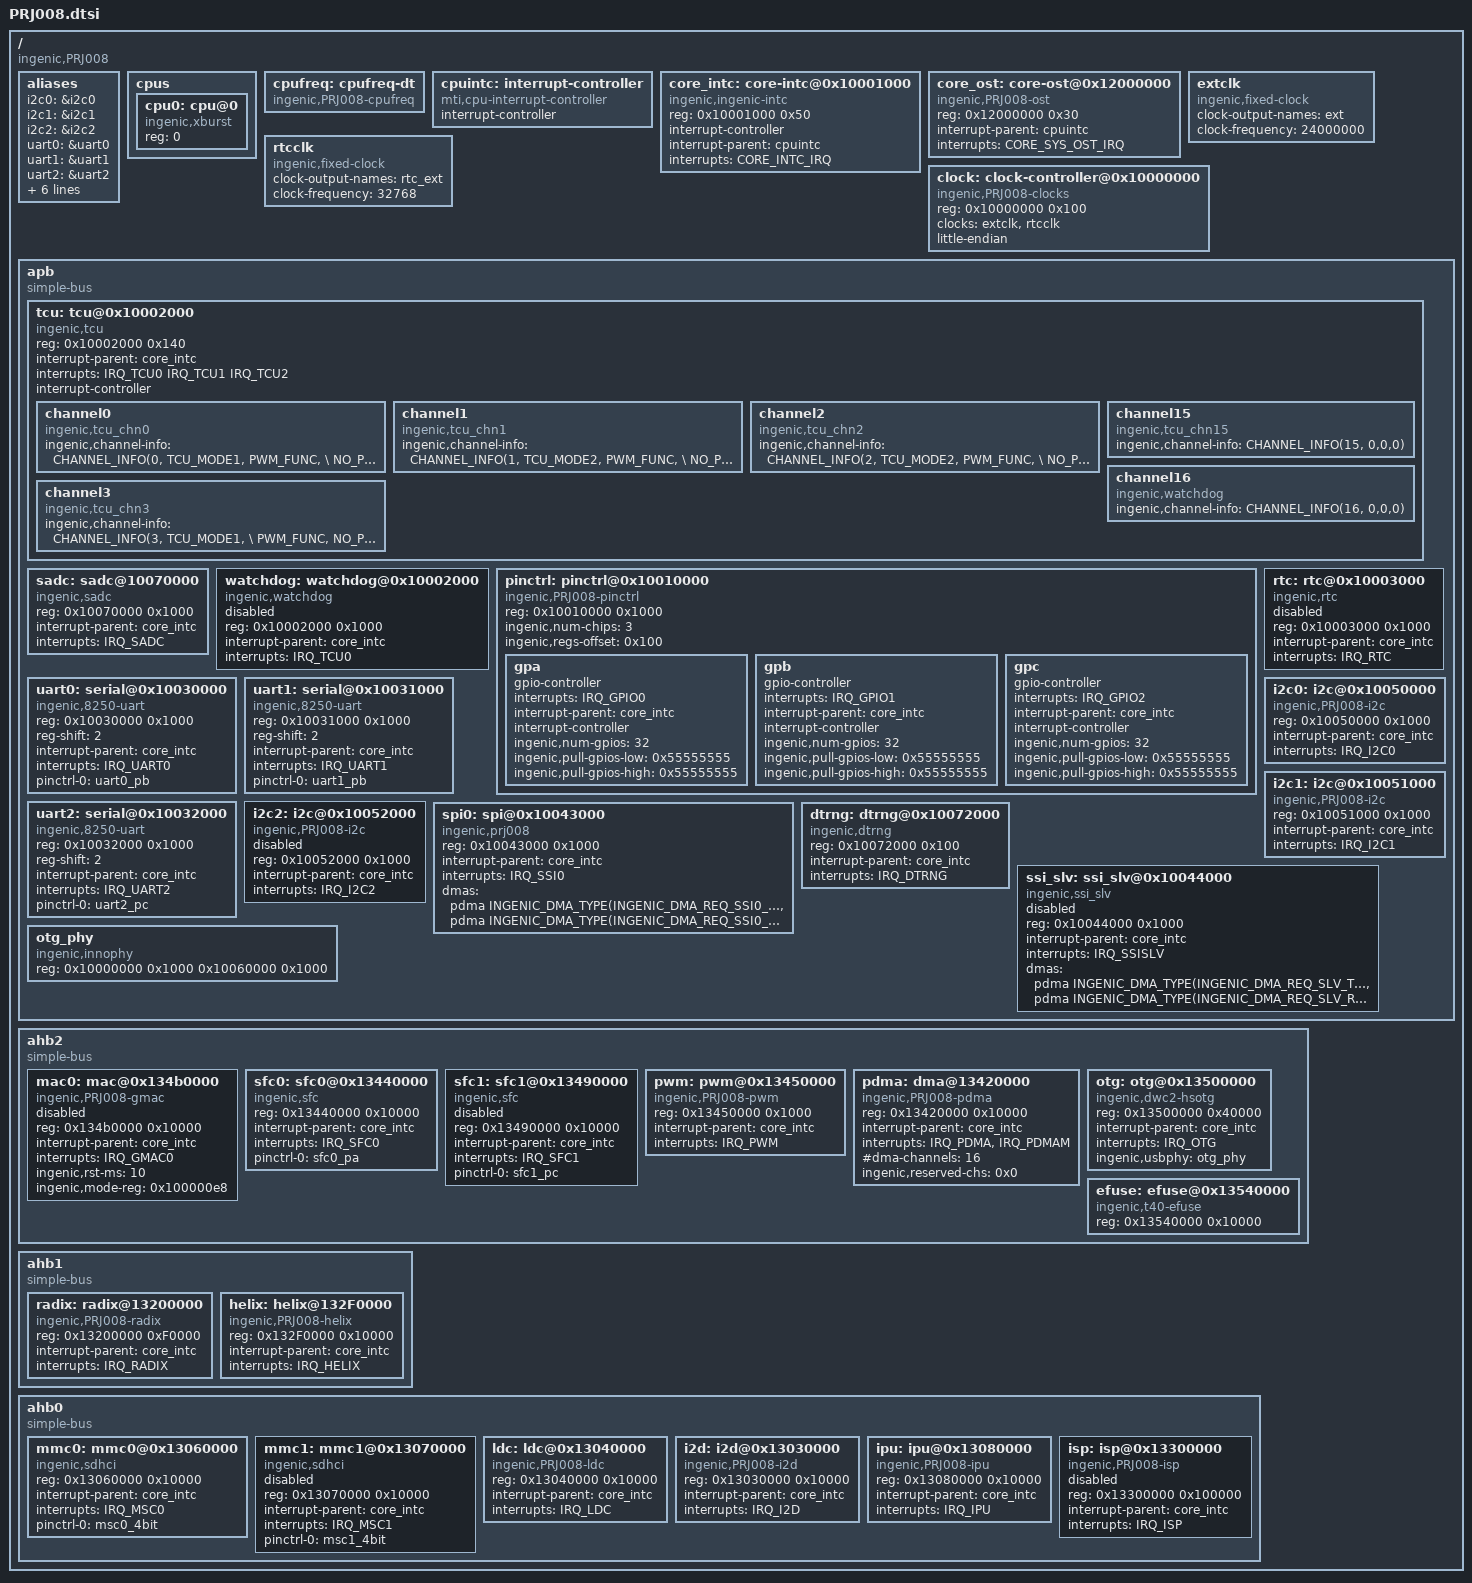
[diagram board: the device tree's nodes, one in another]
#include <dt-bindings/interrupt-controller/PRJ008-irq.h>
#include <dt-bindings/clock/ingenic-tcu.h>
#include <dt-bindings/sound/ingenic-baic.h>
#include <dt-bindings/net/ingenic_gmac.h>
#include <dt-bindings/dma/ingenic-pdma.h>

/ {
	#address-cells = <1>;
	#size-cells = <1>;
	compatible = "ingenic,PRJ008";

	aliases: aliases {
		i2c0 = &i2c0;
		i2c1 = &i2c1;
		i2c2 = &i2c2;
		uart0 = &uart0;
		uart1 = &uart1;
		uart2 = &uart2;
		mmc0 = &mmc0;
		mmc1 = &mmc1;
		mac0 = &mac0;
		spi0 = &spi0;
		sfc0 = &sfc0;
		sfc1 = &sfc1;
	};

	cpus: cpus {
		#address-cells = <1>;
		#size-cells = <0>;

		cpu0: cpu@0 {
			compatible = "ingenic,xburst";
			reg = <0>;
//			clock-frequency = <900000000>;
		};
	};

	cpufreq: cpufreq-dt {
		 compatible = "ingenic,PRJ008-cpufreq";
		 status = "okay";
	};

	cpuintc: interrupt-controller {
		#address-cells = <0>;
		#interrupt-cells = <1>;
		interrupt-controller;
//		compatible = "ingenic,cpu-interrupt-controller";
		compatible = "mti,cpu-interrupt-controller";

	};

	core_intc: core-intc@0x10001000 {
		compatible = "ingenic,ingenic-intc";
		reg = <0x10001000 0x50>;
		interrupt-controller;
		#interrupt-cells = <1>;
		/*cpu-intc-map = <0 0x000>,
			           <1 0x100>,
			           <2 0x200>,
			           <3 0x300>;
*/
		interrupt-parent = <&cpuintc>;
		interrupts = <CORE_INTC_IRQ>;
		interrupt-names ="intc";
	};

	core_ost: core-ost@0x12000000 {
		compatible = "ingenic,PRJ008-ost";
		reg = <0x12000000 0x30>;
		interrupt-parent = <&cpuintc>;
		interrupt-names = "sys_ost";
		interrupts = <CORE_SYS_OST_IRQ>;
	};

	extclk: extclk {
		compatible = "ingenic,fixed-clock";
		clock-output-names ="ext";
		#clock-cells = <0>;
		clock-frequency  = <24000000>;
	};

	rtcclk: rtcclk {
		compatible = "ingenic,fixed-clock";
		clock-output-names ="rtc_ext";
		#clock-cells = <0>;
		clock-frequency = <32768>;
    };

	clock: clock-controller@0x10000000 {
		compatible = "ingenic,PRJ008-clocks";
		reg = <0x10000000 0x100>;
		clocks = <&extclk>, <&rtcclk>;
		clock-names = "ext", "rtc_ext";
		#clock-cells = <1>;
		little-endian;
	};

	apb {
		compatible = "simple-bus";
		#address-cells = <1>;
		#size-cells = <1>;
		ranges = <>;
		tcu: tcu@0x10002000 {
				compatible = "ingenic,tcu";
				reg = <0x10002000 0x140>;
				interrupt-parent = <&core_intc>;
				interrupt-names = "tcu_int0", "tcu_int1", "tcu_int2";
				interrupts = <IRQ_TCU0 IRQ_TCU1 IRQ_TCU2>;
				interrupt-controller;
				status = "ok";

				channel0: channel0 {
					compatible = "ingenic,tcu_chn0";
					ingenic,channel-info = <CHANNEL_INFO(0, TCU_MODE1, PWM_FUNC, \
					NO_PWM_IN)>;
				};
				channel1: channel1 {
					compatible = "ingenic,tcu_chn1";
					ingenic,channel-info = <CHANNEL_INFO(1, TCU_MODE2, PWM_FUNC, \
					NO_PWM_IN)>;
				};
				channel2: channel2 {
					compatible = "ingenic,tcu_chn2";
					ingenic,channel-info = <CHANNEL_INFO(2, TCU_MODE2, PWM_FUNC, \
					NO_PWM_IN)>;
				};
				channel3: channel3 {
					compatible = "ingenic,tcu_chn3";
					ingenic,channel-info = <CHANNEL_INFO(3, TCU_MODE1, \
					PWM_FUNC, NO_PWM_IN)>;
				};
				channel15: channel15 {
					compatible = "ingenic,tcu_chn15";
					ingenic,channel-info = <CHANNEL_INFO(15, 0,0,0)>;
				};
				channel16: channel16 {
					compatible = "ingenic,watchdog";
					ingenic,channel-info = <CHANNEL_INFO(16, 0,0,0)>;
				};
		};

        sadc: sadc@10070000 {
			compatible = "ingenic,sadc";
			reg = <0x10070000 0x1000>;
			interrupt-parent = <&core_intc>;
			interrupts = <IRQ_SADC>;
			status = "okay";
		};

        watchdog: watchdog@0x10002000 {
			compatible = "ingenic,watchdog";
			reg = <0x10002000 0x1000>;
			interrupt-parent = <&core_intc>;
			interrupts = <IRQ_TCU0>;
			status = "disabled";
		};

		pinctrl: pinctrl@0x10010000 {
			compatible = "ingenic,PRJ008-pinctrl";
			reg = <0x10010000 0x1000>;
			ingenic,num-chips = <3>;
			ingenic,regs-offset = <0x100>;

			gpa: gpa {
				gpio-controller;
				#gpio-cells = <3>;
				#ingenic,pincfg-cells = <3>;
				#ingenic,pinmux-cells = <2>;
				interrupts = <IRQ_GPIO0>;
				interrupt-parent = <&core_intc>;
				interrupt-controller;
				#interrupt-cells = <3>;
				ingenic,num-gpios = <32>;
				ingenic,pull-gpios-low = <0x55555555>;
				ingenic,pull-gpios-high = <0x55555555>;
			};

			gpb: gpb {
				gpio-controller;
				#gpio-cells = <3>;
				#ingenic,pincfg-cells = <3>;
				#ingenic,pinmux-cells = <2>;
				interrupts = <IRQ_GPIO1>;
				interrupt-parent = <&core_intc>;
				interrupt-controller;
				#interrupt-cells = <3>;
				ingenic,num-gpios = <32>;
				ingenic,pull-gpios-low = <0x55555555>;
				ingenic,pull-gpios-high = <0x55555555>;
			};

			gpc: gpc {
				gpio-controller;
				#gpio-cells = <3>;
				#ingenic,pincfg-cells = <3>;
				#ingenic,pinmux-cells = <2>;
				interrupts = <IRQ_GPIO2>;
				interrupt-parent = <&core_intc>;
				interrupt-controller;
				#interrupt-cells = <3>;
				ingenic,num-gpios = <32>;
				ingenic,pull-gpios-low = <0x55555555>;
				ingenic,pull-gpios-high = <0x55555555>;
			};
		};

		rtc: rtc@0x10003000 {
			compatible = "ingenic,rtc";
			reg = <0x10003000 0x1000>;
			interrupt-parent = <&core_intc>;
			interrupts = <IRQ_RTC>;
			status = "disabled";
		};

		uart0: serial@0x10030000 {
			compatible = "ingenic,8250-uart";
			reg = <0x10030000 0x1000>;
			reg-shift = <2>;
			interrupt-parent = <&core_intc>;
			interrupts = <IRQ_UART0>;
			pinctrl-names = "default";
			pinctrl-0 = <&uart0_pb>;
			status = "okay";
		};
		uart1: serial@0x10031000 {
			compatible = "ingenic,8250-uart";
			reg = <0x10031000 0x1000>;
			reg-shift = <2>;
			interrupt-parent = <&core_intc>;
			interrupts = <IRQ_UART1>;
			pinctrl-names = "default";
			pinctrl-0 = <&uart1_pb>;
			status = "okay";
		};
		uart2: serial@0x10032000 {
			compatible = "ingenic,8250-uart";
			reg = <0x10032000 0x1000>;
			reg-shift = <2>;
			interrupt-parent = <&core_intc>;
			interrupts = <IRQ_UART2>;
			pinctrl-names = "default";
			pinctrl-0 = <&uart2_pc>;
			status = "okay";
		};

		i2c0: i2c@0x10050000 {
			compatible = "ingenic,PRJ008-i2c";
			reg = <0x10050000 0x1000>;
			interrupt-parent = <&core_intc>;
			interrupts = <IRQ_I2C0>;
			#address-cells = <1>;
			#size-cells = <0>;
			status = "okay";
		};

		i2c1: i2c@0x10051000 {
			compatible = "ingenic,PRJ008-i2c";
			reg = <0x10051000 0x1000>;
			interrupt-parent = <&core_intc>;
			interrupts = <IRQ_I2C1>;
			#address-cells = <1>;
			#size-cells = <0>;
			status = "okay";
		};

		i2c2: i2c@0x10052000 {
			compatible = "ingenic,PRJ008-i2c";
			reg = <0x10052000 0x1000>;
			interrupt-parent = <&core_intc>;
			interrupts = <IRQ_I2C2>;
			#address-cells = <1>;
			#size-cells = <0>;
			status = "disabled";
        };


        spi0: spi@0x10043000 {
			compatible = "ingenic,prj008";
			reg = <0x10043000 0x1000>;
			interrupt-parent = <&core_intc>;
			interrupts = <IRQ_SSI0>;
			dmas = <&pdma INGENIC_DMA_TYPE(INGENIC_DMA_REQ_SSI0_TX)>,
				   <&pdma INGENIC_DMA_TYPE(INGENIC_DMA_REQ_SSI0_RX)>;
			dma-names = "tx", "rx";
			#address-cells = <1>;
			#size-cells = <0>;
			status = "okay";
		};
/*
		spi1: spi@0x10044000 {
			compatible = "ingenic,spi";
			reg = <0x10044000 0x1000>;
			interrupt-parent = <&core_intc>;
			interrupts = <IRQ_SSI1>;
			dmas = <&pdma INGENIC_DMA_TYPE(INGENIC_DMA_REQ_SSI1_TX)>,
				   <&pdma INGENIC_DMA_TYPE(INGENIC_DMA_REQ_SSI1_RX)>;
			dma-names = "tx", "rx";
			#address-cells = <1>;
			#size-cells = <0>;
			status = "disabled";
		};
*/

		dtrng: dtrng@0x10072000 {
			compatible = "ingenic,dtrng";
			reg = <0x10072000 0x100>;
			interrupt-parent = <&core_intc>;
			interrupts = <IRQ_DTRNG>;
			status = "okay";
		};

		ssi_slv: ssi_slv@0x10044000 {
			compatible = "ingenic,ssi_slv";
			reg = <0x10044000 0x1000>;
			interrupt-parent = <&core_intc>;
			interrupts = <IRQ_SSISLV>;
			dmas = <&pdma INGENIC_DMA_TYPE(INGENIC_DMA_REQ_SLV_TX)>,
				   <&pdma INGENIC_DMA_TYPE(INGENIC_DMA_REQ_SLV_RX)>;
			dma-names = "tx", "rx";
			#address-cells = <1>;
			#size-cells = <0>;
			status = "disabled";
		};

		otg_phy: otg_phy {
			compatible = "ingenic,innophy";
			reg = <0x10000000 0x1000 0x10060000 0x1000>;
		};
	};

	ahb2 {
		compatible = "simple-bus";
		#address-cells = <1>;
		#size-cells = <1>;
		ranges = <>;

/*
		aes: aes@0x13430000 {
			compatible = "ingenic,aes";
			reg = <0x13430000 0x10000>;
			interrupt-parent = <&core_intc>;
			interrupts = <IRQ_AES>;
			status = "okay";
		};
		hash: hash@0x13480000 {
			compatible = "ingenic,hash";
			reg = <0x13480000 0x10000>;
			interrupt-parent = <&core_intc>;
			interrupts = <IRQ_HASH>;
			status = "okay";
		};
		rsa: rsa@0x134c0000 {
			compatible = "ingenic,rsa";
			reg = <0x134c0000 0x10000>;
			interrupt-parent = <&core_intc>;
			interrupts = <IRQ_RSA>;
			status = "okay";
		};
*/

		mac0: mac@0x134b0000 {
			compatible = "ingenic,PRJ008-gmac", "snps,dwmac-3.72a";
			reg = <0x134b0000 0x10000>;
			interrupt-parent = <&core_intc>;
			interrupts = <IRQ_GMAC0>;
			interrupt-names = "macirq";
			status = "disabled";
			ingenic,rst-ms = <10>;
			ingenic,mode-reg = <0x100000e8>;
		};

		sfc0: sfc0@0x13440000 {
			compatible = "ingenic,sfc";
			reg = <0x13440000 0x10000>;
			interrupt-parent = <&core_intc>;
			interrupts = <IRQ_SFC0>;
			pinctrl-names = "default";
			pinctrl-0 = <&sfc0_pa>;
			status = "okay";
		};

		sfc1: sfc1@0x13490000 {
			compatible = "ingenic,sfc";
			reg = <0x13490000 0x10000>;
			interrupt-parent = <&core_intc>;
			interrupts = <IRQ_SFC1>;
			pinctrl-names = "default";
			pinctrl-0 = <&sfc1_pc>;
			status = "disabled";
		};

		pwm: pwm@0x13450000 {
			compatible = "ingenic,PRJ008-pwm";
			reg = <0x13450000 0x1000>;
			interrupt-parent = <&core_intc>;
			interrupts = <IRQ_PWM>;
			#address-cells = <1>;
			#size-cells = <0>;
			status = "okay";
		};

		pdma: dma@13420000 {
			compatible = "ingenic,PRJ008-pdma";
			reg = <0x13420000 0x10000>;
			interrupt-parent = <&core_intc>;
			interrupt-names = "pdma", "pdmam";
			interrupts = <IRQ_PDMA>, <IRQ_PDMAM>;
			#dma-channels = <16>;
			#dma-cells = <1>;
			ingenic,reserved-chs = <0x0>;
		};

		otg: otg@0x13500000 {
			compatible = "ingenic,dwc2-hsotg";
			reg = <0x13500000 0x40000>;
			interrupt-parent = <&core_intc>;
			interrupts = <IRQ_OTG>;
			ingenic,usbphy=<&otg_phy>;
			status = "okay";
		};

		efuse: efuse@0x13540000 {
			compatible = "ingenic,t40-efuse";
			reg = <0x13540000 0x10000>;
			status = "okay";
		};
	};

	ahb1 {
		compatible = "simple-bus";
		#address-cells = <1>;
		#size-cells = <1>;
		ranges = <>;

		radix: radix@13200000 {
		   compatible = "ingenic,PRJ008-radix";
		   reg = <0x13200000 0xF0000>;
		   interrupt-parent = <&core_intc>;
		   interrupts = <IRQ_RADIX>;
		   status = "okay";
		};
		helix: helix@132F0000 {
			compatible = "ingenic,PRJ008-helix";
			reg = <0x132F0000 0x10000>;
			interrupt-parent = <&core_intc>;
			interrupts = <IRQ_HELIX>;
			status = "okay";
		};
	};

	ahb0 {
		compatible = "simple-bus";
		#address-cells = <1>;
		#size-cells = <1>;
		ranges = <>;

        mmc0: mmc0@0x13060000 {
			compatible = "ingenic,sdhci";
			reg = <0x13060000 0x10000>;
			status = "okay";
			interrupt-parent = <&core_intc>;
			interrupts = <IRQ_MSC0>;
			pinctrl-names ="default";
			pinctrl-0 = <&msc0_4bit>;
		};

		mmc1: mmc1@0x13070000 {
			compatible = "ingenic,sdhci";
			reg = <0x13070000 0x10000>;
			status = "disabled";
			interrupt-parent = <&core_intc>;
			interrupts = <IRQ_MSC1>;
			pinctrl-names ="default";
			pinctrl-0 = <&msc1_4bit>;
		};

		ldc: ldc@0x13040000 {
			compatible = "ingenic,PRJ008-ldc";
			reg = <0x13040000 0x10000>;
			interrupt-parent = <&core_intc>;
			interrupts = <IRQ_LDC>;
			status = "okay";
		};

		i2d: i2d@0x13030000 {
			compatible = "ingenic,PRJ008-i2d";
			reg = <0x13030000 0x10000>;
			interrupt-parent = <&core_intc>;
			interrupts = <IRQ_I2D>;
			status = "okay";
		};

		ipu: ipu@0x13080000 {
			compatible = "ingenic,PRJ008-ipu";
			reg = <0x13080000 0x10000>;
			interrupt-parent = <&core_intc>;
			interrupts = <IRQ_IPU>;
			status = "okay";
		};

		isp: isp@0x13300000 {
			compatible = "ingenic,PRJ008-isp";
			reg = <0x13300000 0x100000>;
			interrupt-parent = <&core_intc>;
			interrupts = <IRQ_ISP>;
			status = "disabled";
		};
	};

};
#include "PRJ008-pinctrl.dtsi"
